AUTOSAR XML (schema 4-0-3)
package /ComponentTypes
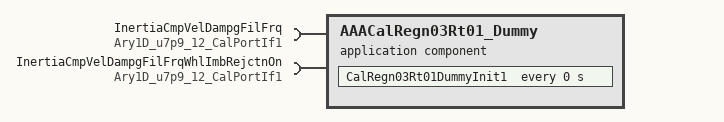
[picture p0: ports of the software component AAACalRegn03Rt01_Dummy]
  application sw component type AAACalRegn03Rt01_Dummy
    require port InertiaCmpVelDampgFilFrq: parameter-require-com-spec{init-value=12 x 8192, parameter=Ary1D}, required-interface=Ary1D_u7p9_12_CalPortIf1
    require port InertiaCmpVelDampgFilFrqWhlImbRejctnOn: parameter-require-com-spec{init-value=12 x 8192, parameter=Ary1D}, required-interface=Ary1D_u7p9_12_CalPortIf1
    behavior AAACalRegn03Rt01_Dummy_InternalBehavior: supports-multiple-instantiation=true
      timing event AAACalRegn03Rt01_Dummy_InitEvent: start-on-event=CalRegn03Rt01DummyInit1, period=0
      runnable CalRegn03Rt01DummyInit1
  swc implementation AAACalRegn03Rt00_Dummy_Implementation: behavior=AAACalRegn03Rt01_Dummy_InternalBehavior
    code-descriptors:
      code Default: artifact-descriptors=autosar-engineering-object={short-label=Default, category=SWSRC}
